# LPC83x register map
File version: 0.2
CPU: CM0PLUS r0p1, little endian, no MPU, no FPU, 2 interrupt priority bits
Registers are 32-bit, read-write, reset 0x0 unless marked. A register's access mark holds for its fields unless they carry their own. Offsets are from the block's base; [hi:lo] are bit positions; {n}, {i} and the like mark numbered series.

## SWM — Switch matrix (SWM)
Base 0x4000C000
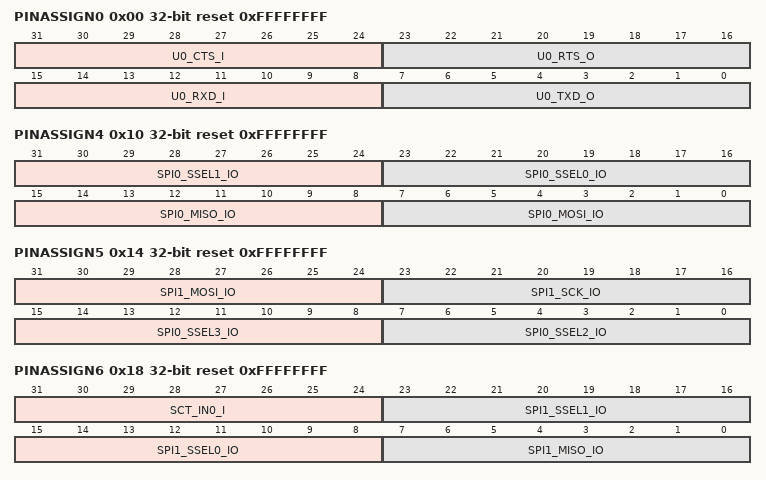
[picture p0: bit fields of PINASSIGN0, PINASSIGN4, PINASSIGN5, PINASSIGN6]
0x00 PINASSIGN0 reset 0xFFFFFFFF — Pin assign register 0. Assign movable functions U0_TXD, U0_RXD, U0_RTS, U0_CTS.
  [31:24] U0_CTS_I — U0_CTS function assignment. The value is the pin number to be assigned to this function. The following pins are available: PIO0_0 (= 0) to PIO0_28 (= 0x1C).
  [23:16] U0_RTS_O — U0_RTS function assignment. The value is the pin number to be assigned to this function. The following pins are available: PIO0_0 (= 0) to PIO0_28 (= 0x1C).
  [15:8] U0_RXD_I — U0_RXD function assignment. The value is the pin number to be assigned to this function. The following pins are available: PIO0_0 (= 0) to PIO0_28 (= 0x1C).
  [7:0] U0_TXD_O — U0_TXD function assignment. The value is the pin number to be assigned to this function. The following pins are available: PIO0_0 (= 0) to PIO0_28 (= 0x1C).
0x04 PINASSIGN1 reset 0xFFFFFFFF — Pin assign register 1. Assign movable functions U0_SCLK.
  [7:0] U0_SCLK_IO — U0_SCLK function assignment. The value is the pin number to be assigned to this function. The following pins are available: PIO0_0 (= 0) to PIO0_28 (= 0x1C).
0x0C PINASSIGN3 reset 0xFFFFFFFF — Pin assign register 3. Assign movable function U2_RTS, U2_CTS, U2_SCLK, SPI0_SCK.
  [31:24] SPI0_SCK_IO — SPI0_SCK function assignment. The value is the pin number to be assigned to this function. The following pins are available: PIO0_0 (= 0) to PIO0_28 (= 0x1C).
0x10 PINASSIGN4 reset 0xFFFFFFFF — Pin assign register 4. Assign movable functions SPI0_MOSI, SPI0_MISO, SPI0_SSEL0, SPI0_SSEL1.
  [31:24] SPI0_SSEL1_IO — SPI0_SSEL1 function assignment. The value is the pin number to be assigned to this function. The following pins are available: PIO0_0 (= 0) to PIO0_28 (= 0x1C).
  [23:16] SPI0_SSEL0_IO — SPI0_SSEL0 function assignment. The value is the pin number to be assigned to this function. The following pins are available: PIO0_0 (= 0) to PIO0_28 (= 0x1C).
  [15:8] SPI0_MISO_IO — SPI0_MISIO function assignment. The value is the pin number to be assigned to this function. The following pins are available: PIO0_0 (= 0) to PIO0_28 (= 0x1C).
  [7:0] SPI0_MOSI_IO — SPI0_MOSI function assignment. The value is the pin number to be assigned to this function. The following pins are available: PIO0_0 (= 0) to PIO0_28 (= 0x1C).
0x14 PINASSIGN5 reset 0xFFFFFFFF — Pin assign register 5. Assign movable functions SPI0_SSEL2, SPI0_SSEL3, SPI1_SCK, SPI1_MOSI
  [31:24] SPI1_MOSI_IO — SPI1_MOSI function assignment. The value is the pin number to be assigned to this function. The following pins are available: PIO0_0 (= 0) to PIO0_28 (= 0x1C).
  [23:16] SPI1_SCK_IO — SPI1_SCK function assignment. The value is the pin number to be assigned to this function. The following pins are available: PIO0_0 (= 0) to PIO0_28 (= 0x1C).
  [15:8] SPI0_SSEL3_IO — SPI0_SSEL3 function assignment. The value is the pin number to be assigned to this function. The following pins are available: PIO0_0 (= 0) to PIO0_28 (= 0x1C).
  [7:0] SPI0_SSEL2_IO — SPI0_SSEL2 function assignment. The value is the pin number to be assigned to this function. The following pins are available: PIO0_0 (= 0) to PIO0_28 (= 0x1C).
0x18 PINASSIGN6 reset 0xFFFFFFFF — Pin assign register 6. Assign movable functions SPI1_MISO, SPI1_SSEL0, SPI1_SSEL1, SCT0_IN0.
  [31:24] SCT_IN0_I — SCT_IN0 function assignment. The value is the pin number to be assigned to this function. The following pins are available: PIO0_0 (= 0) to PIO0_28 (= 0x1C).
  [23:16] SPI1_SSEL1_IO — SPI1_SSEL1 function assignment. The value is the pin number to be assigned to this function. The following pins are available: PIO0_0 (= 0) to PIO0_28 (= 0x1C).
  [15:8] SPI1_SSEL0_IO — SPI1_SSEL0 function assignment. The value is the pin number to be assigned to this function. The following pins are available: PIO0_0 (= 0) to PIO0_28 (= 0x1C).
  [7:0] SPI1_MISO_IO — SPI1_MISO function assignment. The value is the pin number to be assigned to this function. The following pins are available: PIO0_0 (= 0) to PIO0_28 (= 0x1C).
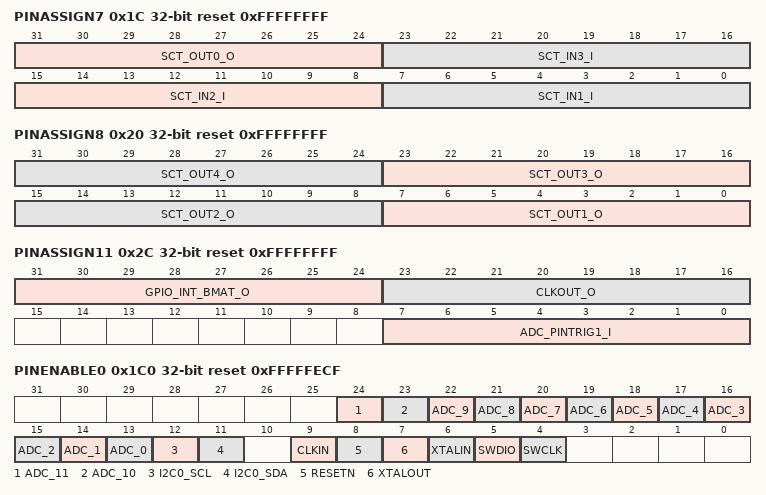
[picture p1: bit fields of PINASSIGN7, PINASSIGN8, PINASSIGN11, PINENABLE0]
0x1C PINASSIGN7 reset 0xFFFFFFFF — Pin assign register 7. Assign movable functions SCT_IN1, SCT_IN2, SCT_IN3, SCT_OUT0.
  [31:24] SCT_OUT0_O — SCT_OUT0 function assignment. The value is the pin number to be assigned to this function. The following pins are available: PIO0_0 (= 0) to PIO0_28 (= 0x1C).
  [23:16] SCT_IN3_I — SCT_IN3 function assignment. The value is the pin number to be assigned to this function. The following pins are available: PIO0_0 (= 0) to PIO0_28 (= 0x1C).
  [15:8] SCT_IN2_I — SCT_IN2 function assignment. The value is the pin number to be assigned to this function. The following pins are available: PIO0_0 (= 0) to PIO0_28 (= 0x1C).
  [7:0] SCT_IN1_I — SCT_IN1 function assignment. The value is the pin number to be assigned to this function. The following pins are available: PIO0_0 (= 0) to PIO0_28 (= 0x1C).
0x20 PINASSIGN8 reset 0xFFFFFFFF — Pin assign register 8. Assign movable functions SCT_OUT1, SCT_OUT2, SCT_OUT3, SCT_OUT4.
  [8n-1:8n-8] SCT_OUT{n}_O (n=1..4) — SCT_OUT{n} function assignment. The value is the pin number to be assigned to this function. The following pins are available: PIO0_0 (= 0) to PIO0_28 (= 0x1C).
0x24 PINASSIGN9 reset 0xFFFFFFFF — Pin assign register 9. Assign movable functions SCT_OUT5.
  [7:0] SCT_OUT5_O — SCT_OUT5 function assignment. The value is the pin number to be assigned to this function. The following pins are available: PIO0_0 (= 0) to PIO0_28 (= 0x1C).
0x28 PINASSIGN10 reset 0xFFFFFFFF — Pin assign register 10. Assign movable function ADC_PINTRIG0.
  [31:24] ADC_PINTRIG0_I — ADC_PINTRIG0 function assignment. The value is the pin number to be assigned to this function. The following pins are available: PIO0_0 (= 0) to PIO0_28 (= 0x1C).
0x2C PINASSIGN11 reset 0xFFFFFFFF — Pin assign register 11. Assign movable functions ADC_PINTRIG1, CLKOUT, GPIO_INT_BMAT
  [31:24] GPIO_INT_BMAT_O — GPIO_INT_BMAT function assignment. The value is the pin number to be assigned to this function. The following pins are available: PIO0_0 (= 0) to PIO0_28 (= 0x1C).
  [23:16] CLKOUT_O — CLKOUT function assignment. The value is the pin number to be assigned to this function. The following pins are available: PIO0_0 (= 0) to PIO0_28 (= 0x1C).
  [7:0] ADC_PINTRIG1_I — ADC_PINTRIG1 function assignment. The value is the pin number to be assigned to this function. The following pins are available: PIO0_0 (= 0) to PIO0_28 (= 0x1C).
0x1C0 PINENABLE0 reset 0xFFFFFECF — Pin enable register 0. Enables fixed-pin functions SWCLK, SWDIO, XTALIN, XTALOUT, RESET, CLKIN.
  [24] ADC_11 — ADC_11 function select.
    0=ADC_11_ENABLED_ON_PI (ADC_11 enabled on pin PIO0_4.); 1=ADC_11_DISABLED
  [23] ADC_10 — ADC_10 function select.
    0=ADC_10_ENABLED_ON_PI (ADC_10 enabled on pin PIO0_13.); 1=ADC_10_DISABLED
  [22] ADC_9 — ADC_9 function select.
    0=ADC_9_ENABLED_ON_PIN (ADC_9 enabled on pin PIO0_17.); 1=ADC_9_DISABLED
  [21] ADC_8 — ADC_8 function select.
    0=ADC_8_ENABLED_ON_PIN (ADC_8 enabled on pin PIO0_18.); 1=ADC_8_DISABLED
  [20] ADC_7 — ADC_7 function select.
    0=ADC_7_ENABLED_ON_PIN (ADC_7 enabled on pin PIO0_19.); 1=ADC_7_DISABLED
  [19] ADC_6 — ADC_6 function select.
    0=ADC_6_ENABLED_ON_PIN (ADC_6 enabled on pin PIO0_20.); 1=ADC_6_DISABLED
  [18] ADC_5 — ADC_5 function select.
    0=ADC_5_ENABLED_ON_PIN (ADC_5 enabled on pin PIO0_21.); 1=ADC_5_DISABLED
  [17] ADC_4 — ADC_4 function select.
    0=ADC_4_ENABLED_ON_PIN (ADC_4 enabled on pin PIO0_22.); 1=ADC_4_DISABLED
  [16] ADC_3 — ADC_3 function select.
    0=ADC_3_ENABLED_ON_PIN (ADC_3 enabled on pin PIO0_23.); 1=ADC_3_DISABLED
  [15] ADC_2 — ADC_2 function select.
    0=ADC_2_ENABLED_ON_PIN (ADC_2 enabled on pin PIO0_14.); 1=ADC_2_DISABLED
  [14] ADC_1 — ADC_1 function select.
    0=ADC_1_ENABLED_ON_PIN (ADC_1 enabled on pin PIO0_6.); 1=ADC_1_DISABLED
  [13] ADC_0 — ADC_0 function select.
    0=ADC_0_ENABLED_ON_PIN (ADC_0 enabled on pin PIO0_7.); 1=ADC_0_DISABLED
  [12] I2C0_SCL — I2C0_SCL function select.
    0=I2C0_SCL_ENABLED_ON (I2C0_SCL enabled on pin PIO0_10.); 1=I2C0_SCL_DISABLED
  [11] I2C0_SDA — I2C0_SDA function select.
    0=I2C0_SDA_ENABLED_ON (I2C0_SDA enabled on pin PIO0_11.); 1=I2C0_SDA_DISABLED
  [9] CLKIN — CLKIN function select.
    0=CLKIN_ENABLED_ON_PIN (CLKIN enabled on pin PIO0_1.); 1=CLKIN_DISABLED
  [8] RESETN — RESETN function select.
    0=RESETN_ENABLED_ON_PI (RESETN enabled on pin PIO0_5.); 1=RESETN_DISABLED
  [7] XTALOUT — XTALOUT function select.
    0=XTALOUT_ENABLED_ON_P (XTALOUT enabled on pin PIO0_9.); 1=XTALOUT_DISABLED
  [6] XTALIN — XTALIN function select.
    0=XTALIN_ENABLED_ON_PI (XTALIN enabled on pin PIO0_8.); 1=XTALIN_DISABLED
  [5] SWDIO — SWDIO function select.
    0=SWDIO_ENABLED_ON_PIN (SWDIO enabled on pin PIO0_2.); 1=SWDIO_DISABLED
  [4] SWCLK — SWCLK function select.
    0=SWCLK_ENABLED_ON_PIN (SWCLK enabled on pin PIO0_3.); 1=SWCLK_DISABLED
